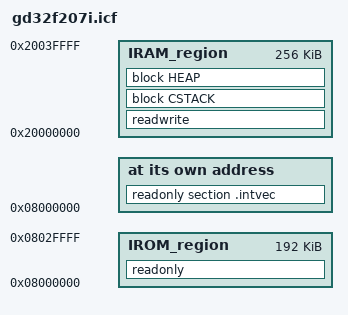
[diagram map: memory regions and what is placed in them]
/*###ICF### Section handled by ICF editor, don't touch! ****/
/*-Specials-*/
define symbol __ICFEDIT_intvec_start__ = 0x08000000;
/*-Memory Regions-*/
define symbol __ICFEDIT_region_IROM1_start__ = 0x08000000;
define symbol __ICFEDIT_region_IROM1_end__   = 0x0802FFFF;
define symbol __ICFEDIT_region_IRAM1_start__ = 0x20000000;
define symbol __ICFEDIT_region_IRAM1_end__   = 0x2003FFFF;
/*-Sizes-*/
define symbol __ICFEDIT_size_cstack__     = 0x800;
define symbol __ICFEDIT_size_heap__       = 0x100;
/**** End of ICF editor section. ###ICF###*/

define memory mem with size = 4G;
define region IROM_region = mem:[from __ICFEDIT_region_IROM1_start__ to __ICFEDIT_region_IROM1_end__];
define region IRAM_region = mem:[from __ICFEDIT_region_IRAM1_start__ to __ICFEDIT_region_IRAM1_end__];

initialize by copy with packing = zeros { readwrite };

place at address mem:__ICFEDIT_intvec_start__ { readonly section .intvec };
place in IROM_region  { readonly };

define block CSTACK with alignment = 8, size = __ICFEDIT_size_cstack__ { };
define block HEAP   with alignment = 8, size = __ICFEDIT_size_heap__   { };
place in IRAM_region { readwrite, block CSTACK, block HEAP };
